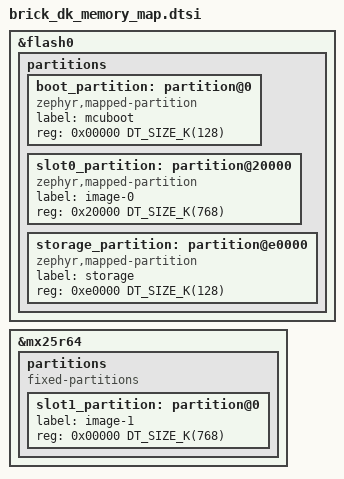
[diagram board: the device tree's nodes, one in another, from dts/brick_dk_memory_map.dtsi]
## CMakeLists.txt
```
# Brick V1 — nRF52840 platform application (nRF Connect SDK v3.4.1 / Zephyr).
#
# Build only with scripts/build.sh (sysbuild: MCUboot + this application, dev key).
# This application does NOT link firmware/ (libbrickcore) yet: bk_hal_t is
# connected in a separate PR (issue #10). Nothing from Nordic/Zephyr may be
# included from firmware/.
cmake_minimum_required(VERSION 3.20.0)

find_package(Zephyr REQUIRED HINTS $ENV{ZEPHYR_BASE})
project(brick_nrf52840)

target_sources(app PRIVATE src/main.c)
```

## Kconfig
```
# Brick V1 — application options (nRF52840 platform glue).

mainmenu "Brick V1 nRF52840 platform"

menu "Brick image confirmation (bring-up tests)"

choice BRICK_CONFIRM_POLICY
	prompt "What the application does after boot"
	default BRICK_CONFIRM_AFTER_SELFTEST

config BRICK_CONFIRM_AFTER_SELFTEST
	bool "Confirm the image after a successful self-test (normal behaviour)"

config BRICK_TEST_NEVER_CONFIRM
	bool "TEST ONLY: run normally but never confirm (MCUboot must revert on next reset)"

config BRICK_TEST_CRASH_BEFORE_CONFIRM
	bool "TEST ONLY: fault right after start, before confirming (MCUboot must revert)"

config BRICK_TEST_HANG_BEFORE_CONFIRM
	bool "TEST ONLY: hang right after start, watchdog resets, before confirming"

endchoice

config BRICK_SELFTEST_WDT_TIMEOUT_MS
	int "Watchdog timeout while the image is not confirmed [ms]"
	default 5000

endmenu

source "Kconfig.zephyr"
```

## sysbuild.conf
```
# Brick V1 — sysbuild options (nRF Connect SDK v3.4.1).
# Only options that are checked by a real build are listed here; see
# docs/NRF52840_BRINGUP.md for the state of hardware verification.

SB_CONFIG_BOOTLOADER_MCUBOOT=y

# Swap with revert, no scratch partition (needs equal sector size on both slots).
# New image is started in "test" state and reverts unless the application
# confirms it after its self-test (src/main.c).
SB_CONFIG_MCUBOOT_MODE_SWAP_USING_MOVE=y

# ECDSA P-256 (NCS default for nRF52840, stated explicitly on purpose).
SB_CONFIG_BOOT_SIGNATURE_TYPE_ECDSA_P256=y

# The signing key is NOT set here: scripts/build.sh passes the absolute path of the
# DEV key generated by scripts/gen_dev_key.sh (never committed).
# sysbuild.cmake refuses to build with Nordic's public sample key.
```

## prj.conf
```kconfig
# Brick V1 — application configuration (nRF52840 DK bring-up, NCS v3.4.1).
# Release hardening rules (docs/FIRMWARE_UPDATE_NRF52840.md): only img + os MCUmgr
# groups; no shell, fs, stat, taskstat, settings management over USB or BLE.

# --- image is built for MCUboot (header, signature slot, trailer) -------------------
CONFIG_BOOTLOADER_MCUBOOT=y

# --- flash: internal + external QSPI NOR (slot1 lives there) ------------------------
CONFIG_FLASH=y
CONFIG_FLASH_MAP=y
CONFIG_STREAM_FLASH=y
CONFIG_NORDIC_QSPI_NOR=y
CONFIG_NORDIC_QSPI_NOR_FLASH_LAYOUT_PAGE_SIZE=4096
CONFIG_NORDIC_QSPI_NOR_STACK_WRITE_BUFFER_SIZE=16

# --- watchdog: a hung unconfirmed image must reset, so MCUboot can revert ------------
CONFIG_WATCHDOG=y

# --- logs and console on the J-Link virtual COM port (uart0) ------------------------
CONFIG_GPIO=y
CONFIG_SERIAL=y
CONFIG_CONSOLE=y
CONFIG_UART_CONSOLE=y
CONFIG_LOG=y
CONFIG_LOG_MAX_LEVEL=3

# --- USB device (new stack) with one CDC ACM port carrying MCUmgr/SMP ----------------
CONFIG_USB_DEVICE_STACK_NEXT=y
CONFIG_UART_LINE_CTRL=y
CONFIG_CDC_ACM_SERIAL_INITIALIZE_AT_BOOT=y
CONFIG_CDC_ACM_SERIAL_MANUFACTURER_STRING="Brick (DEV)"
CONFIG_CDC_ACM_SERIAL_PRODUCT_STRING="Brick V1 (DEV)"
# DEV identity (Zephyr project VID/PID). Production needs own VID/PID: open item.

# --- MCUmgr / SMP over the CDC ACM UART ---------------------------------------------
CONFIG_NET_BUF=y
CONFIG_ZCBOR=y
CONFIG_CRC=y
CONFIG_BASE64=y
CONFIG_MCUMGR=y
CONFIG_UART_MCUMGR=y
CONFIG_MCUMGR_TRANSPORT_UART=y
CONFIG_IMG_MANAGER=y
CONFIG_MCUMGR_GRP_IMG=y
CONFIG_MCUMGR_GRP_OS=y
# CLI needs the buffer geometry and bootloader type to choose upload chunk size.
CONFIG_MCUMGR_GRP_OS_MCUMGR_PARAMS=y
CONFIG_MCUMGR_GRP_OS_BOOTLOADER_INFO=y
# Not needed in the product: leave off.
CONFIG_MCUMGR_GRP_OS_ECHO=n
CONFIG_MCUMGR_GRP_OS_TASKSTAT=n
CONFIG_MCUMGR_GRP_STAT=n
CONFIG_MCUMGR_GRP_FS=n
CONFIG_MCUMGR_GRP_SHELL=n
CONFIG_SHELL=n

# Some SMP handlers need a big stack (Nordic smp_svr sample values).
CONFIG_SYSTEM_WORKQUEUE_STACK_SIZE=2304
CONFIG_MAIN_STACK_SIZE=2176
```

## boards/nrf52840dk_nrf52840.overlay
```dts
/*
 * Application devicetree for the nRF52840 DK.
 * Partitions come from the shared map; USB CDC ACM carries MCUmgr/SMP
 * (the "nRF USB" connector J3, NOT the J-Link port).
 * Console and logs stay on the J-Link VCOM UART (uart0).
 */

#include "../dts/brick_dk_memory_map.dtsi"

/ {
	chosen {
		zephyr,uart-mcumgr = &cdc_acm_uart0;
	};
};

&zephyr_udc0 {
	cdc_acm_uart0: cdc_acm_uart0 {
		compatible = "zephyr,cdc-acm-uart";
	};
};
```

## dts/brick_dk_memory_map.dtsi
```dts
/*
 * Brick V1 bring-up memory map for the nRF52840 DK (nrf52840dk/nrf52840).
 *
 * ONE file, included by the application overlay AND by the MCUboot overlay:
 * every sysbuild image must see exactly the same partitions
 * (NCS doc "Partitioning device memory"). Do not edit one side only.
 *
 * STATUS: DK BRING-UP LAYOUT, NOT FROZEN. The sizes follow the estimate in
 * docs/FIRMWARE_UPDATE_NRF52840.md (128 KiB / 768 KiB / 128 KiB). Real MCUboot
 * and application sizes are measured in docs/NRF52840_BRINGUP.md. A production
 * layout is decided only after hardware tests (power loss, swap, revert) and
 * must never change between shipped builds.
 *
 * Internal flash (nRF52840, 1 MiB, erase page 4 KiB, write block 4 B):
 *   0x00000 .. 0x1ffff  boot_partition     128 KiB  MCUboot + USB CDC serial recovery
 *   0x20000 .. 0xdffff  slot0_partition    768 KiB  running image (header + app + trailer)
 *   0xe0000 .. 0xfffff  storage_partition  128 KiB  settings / BKSV profile (not touched by DFU)
 *
 * External QSPI NOR (DK: MX25R6435F, 8 MiB, erase sector 4 KiB):
 *   0x000000 .. 0x0bffff  slot1_partition  768 KiB  secondary slot, same size as slot0
 *   0x0c0000 .. 0x7fffff  unallocated      reserved for assets, NOT XIP code
 *
 * Swap mode is "swap using move" (no scratch partition); it needs both slots
 * to have the same sector size, which holds here (4 KiB on both devices).
 */

/delete-node/ &boot_partition;
/delete-node/ &slot0_partition;
/delete-node/ &slot1_partition;
/delete-node/ &storage_partition;

&flash0 {
	partitions {
		boot_partition: partition@0 {
			compatible = "zephyr,mapped-partition";
			label = "mcuboot";
			reg = <0x00000 DT_SIZE_K(128)>;
		};

		slot0_partition: partition@20000 {
			compatible = "zephyr,mapped-partition";
			label = "image-0";
			reg = <0x20000 DT_SIZE_K(768)>;
		};

		storage_partition: partition@e0000 {
			compatible = "zephyr,mapped-partition";
			label = "storage";
			reg = <0xe0000 DT_SIZE_K(128)>;
		};
	};
};

&mx25r64 {
	partitions {
		compatible = "fixed-partitions";
		#address-cells = <1>;
		#size-cells = <1>;

		slot1_partition: partition@0 {
			label = "image-1";
			reg = <0x00000 DT_SIZE_K(768)>;
		};
	};
};
```

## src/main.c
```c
/*
 * Brick V1 — nRF52840 platform bring-up application.
 *
 * What this is: the smallest application that proves the update chain on the
 * nRF52840 DK: reports its version and image state, runs a self-test and only
 * then confirms the MCUboot image, and carries MCUmgr/SMP over USB CDC ACM.
 *
 * What this is not: the Brick console. libbrickcore (firmware/) is NOT linked
 * here; bk_hal_t is connected in a separate change.
 */
#include <zephyr/kernel.h>
#include <zephyr/app_version.h>
#include <zephyr/device.h>
#include <zephyr/dfu/mcuboot.h>
#include <zephyr/drivers/gpio.h>
#include <zephyr/drivers/watchdog.h>
#include <zephyr/logging/log.h>
#include <zephyr/storage/flash_map.h>

LOG_MODULE_REGISTER(brick, LOG_LEVEL_INF);

#define LED0_NODE DT_ALIAS(led0)
#define WDT_NODE  DT_ALIAS(watchdog0)

static const struct gpio_dt_spec led = GPIO_DT_SPEC_GET(LED0_NODE, gpios);
static const struct device *const wdt = DEVICE_DT_GET(WDT_NODE);
static int wdt_channel = -1;

static const char *swap_name(int type)
{
	switch (type) {
	case BOOT_SWAP_TYPE_NONE:
		return "none";
	case BOOT_SWAP_TYPE_TEST:
		return "test";
	case BOOT_SWAP_TYPE_PERM:
		return "permanent";
	case BOOT_SWAP_TYPE_REVERT:
		return "revert";
	case BOOT_SWAP_TYPE_FAIL:
		return "fail";
	default:
		return "unknown";
	}
}

/*
 * The nRF52840 watchdog cannot be stopped once started and keeps running across a soft reset,
 * so main() feeds it for ever and MCUboot feeds it too while it swaps, hashes or waits in serial
 * recovery (CONFIG_BOOT_WATCHDOG_FEED, checked by scripts/verify_build.py).
 */
static int watchdog_start(void)
{
	const struct wdt_timeout_cfg cfg = {
		.flags = WDT_FLAG_RESET_SOC,
		.window = {.min = 0, .max = CONFIG_BRICK_SELFTEST_WDT_TIMEOUT_MS},
	};

	if (!device_is_ready(wdt)) {
		return -ENODEV;
	}
	wdt_channel = wdt_install_timeout(wdt, &cfg);
	if (wdt_channel < 0) {
		return wdt_channel;
	}
	return wdt_setup(wdt, WDT_OPT_PAUSE_HALTED_BY_DBG);
}

static int check_area(const char *name, uint8_t id, size_t *size)
{
	const struct flash_area *fa;
	uint8_t probe[16];
	int rc = flash_area_open(id, &fa);

	if (rc != 0) {
		LOG_ERR("self-test: %s: open failed (%d)", name, rc);
		return rc;
	}
	rc = flash_area_read(fa, 0, probe, sizeof probe);
	*size = fa->fa_size;
	LOG_INF("flash area %-8s id=%u dev=%s off=0x%06lx size=%u KiB", name, id, fa->fa_dev->name,
		(unsigned long)fa->fa_off, (unsigned)(fa->fa_size / 1024U));
	flash_area_close(fa);
	if (rc != 0) {
		LOG_ERR("self-test: %s: read failed (%d)", name, rc);
	}
	return rc;
}

/*
 * Minimal self-test before the image may be confirmed. Real products add: storage
 * integrity (BKSV A/B), hardware revision check, display/input init.
 * Confirming immediately at start would defeat revert, see FIRMWARE_UPDATE_NRF52840.md.
 */
static int self_test(void)
{
	size_t s0 = 0, s1 = 0, st = 0;

	if (check_area("slot0", PARTITION_ID(slot0_partition), &s0) != 0 ||
	    check_area("slot1", PARTITION_ID(slot1_partition), &s1) != 0 ||
	    check_area("storage", PARTITION_ID(storage_partition), &st) != 0) {
		return -EIO;
	}
	if (s1 < s0) {
		LOG_ERR("self-test: slot1 (%u) smaller than slot0 (%u)", (unsigned)s1, (unsigned)s0);
		return -EINVAL;
	}
	return 0;
}

static void blink(int period_ms)
{
	static int64_t last;
	int64_t now = k_uptime_get();

	if (now - last >= period_ms / 2) {
		last = now;
		gpio_pin_toggle_dt(&led);
	}
}

int main(void)
{
	bool confirmed = boot_is_img_confirmed();
	int rc;

	LOG_INF("Brick V1 platform %s, signed version %s, built %s %s", APP_VERSION_EXTENDED_STRING,
		CONFIG_MCUBOOT_IMGTOOL_SIGN_VERSION, __DATE__, __TIME__);
	LOG_INF("image: confirmed=%s, last swap=%s", confirmed ? "yes" : "NO (test)",
		swap_name(mcuboot_swap_type()));

	if (gpio_is_ready_dt(&led)) {
		gpio_pin_configure_dt(&led, GPIO_OUTPUT_INACTIVE);
	}
	rc = watchdog_start();
	if (rc != 0) {
		LOG_ERR("watchdog start failed (%d)", rc);
	}

#if defined(CONFIG_BRICK_TEST_CRASH_BEFORE_CONFIRM)
	if (!confirmed) {
		LOG_WRN("TEST: faulting before confirmation");
		k_panic();
	}
#elif defined(CONFIG_BRICK_TEST_HANG_BEFORE_CONFIRM)
	if (!confirmed) {
		LOG_WRN("TEST: hanging before confirmation, watchdog must reset");
		for (;;) {
			k_busy_wait(1000);
		}
	}
#endif

	if (!confirmed) {
		rc = self_test();
		if (rc != 0) {
			LOG_ERR("self-test FAILED (%d): image stays unconfirmed, MCUboot will revert", rc);
		} else if (IS_ENABLED(CONFIG_BRICK_TEST_NEVER_CONFIRM)) {
			LOG_WRN("TEST: self-test passed, confirmation withheld on purpose");
		} else {
			rc = boot_write_img_confirmed();
			LOG_INF("self-test passed, confirm image: %s (%d)", rc == 0 ? "OK" : "FAILED", rc);
		}
		confirmed = boot_is_img_confirmed();
	}

	LOG_INF("ready: image %s; MCUmgr/SMP on the nRF USB port (CDC ACM)",
		confirmed ? "confirmed" : "NOT confirmed");

	for (;;) {
		if (wdt_channel >= 0) {
			wdt_feed(wdt, wdt_channel);
		}
		blink(confirmed ? 1000 : 200);
		k_sleep(K_MSEC(50));
	}
	return 0;
}
```
